CM_ "IMPORT _nissan_common.dbc";

BO_ 348 GAS_PEDAL: 8 XXX
 SG_ GAS_PEDAL_RAW : 26|11@0+ (1,0) [0|2047] "" XXX
 SG_ GAS_PEDAL : 47|10@0+ (1,0) [0|1023] "" XXX

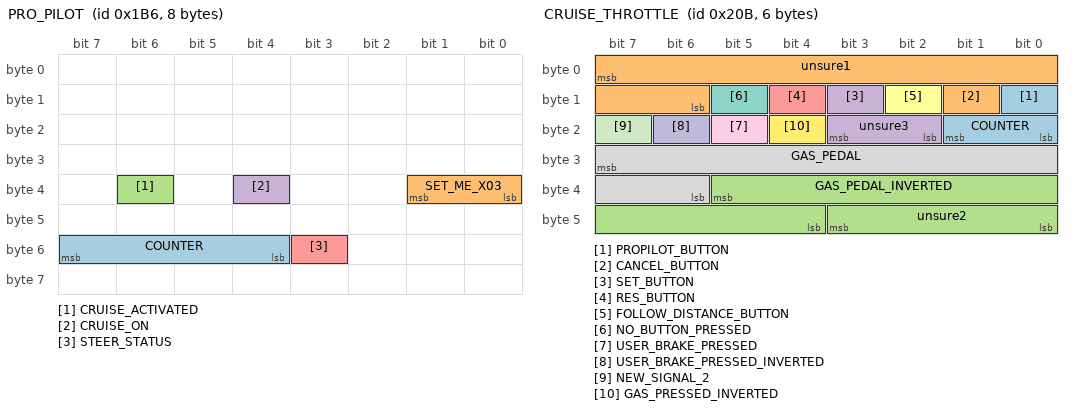
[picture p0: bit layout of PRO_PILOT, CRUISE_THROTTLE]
BO_ 438 PRO_PILOT: 8 XXX
 SG_ COUNTER : 55|4@0+ (1,0) [0|255] "" XXX
 SG_ SET_ME_X03 : 33|2@0+ (1,0) [0|15] "" XXX
 SG_ CRUISE_ACTIVATED : 38|1@0+ (1,0) [0|3] "" XXX
 SG_ CRUISE_ON : 36|1@0+ (1,0) [0|255] "" XXX
 SG_ STEER_STATUS : 51|1@0+ (1,0) [0|3] "" XXX

BO_ 523 CRUISE_THROTTLE: 6 XXX
 SG_ PROPILOT_BUTTON : 8|1@0+ (1,0) [0|1] "" XXX
 SG_ CANCEL_BUTTON : 9|1@0+ (1,0) [0|1] "" XXX
 SG_ GAS_PEDAL_INVERTED : 37|10@0+ (1,0) [0|1023] "" XXX
 SG_ SET_BUTTON : 11|1@0+ (1,0) [0|1] "" XXX
 SG_ RES_BUTTON : 12|1@0+ (1,0) [0|1] "" XXX
 SG_ FOLLOW_DISTANCE_BUTTON : 10|1@0+ (1,0) [0|1] "" XXX
 SG_ NO_BUTTON_PRESSED : 13|1@0+ (1,0) [0|1] "" XXX
 SG_ GAS_PEDAL : 31|10@0+ (1,0) [0|255] "" XXX
 SG_ USER_BRAKE_PRESSED : 21|1@0+ (1,0) [0|1] "" XXX
 SG_ USER_BRAKE_PRESSED_INVERTED : 22|1@0+ (1,0) [0|3] "" XXX
 SG_ NEW_SIGNAL_2 : 23|1@0+ (1,0) [0|1] "" XXX
 SG_ GAS_PRESSED_INVERTED : 20|1@0+ (1,0) [0|255] "" XXX
 SG_ COUNTER : 17|2@0+ (1,0) [0|3] "" XXX
 SG_ unsure1 : 7|10@0+ (1,0) [0|1023] "" XXX
 SG_ unsure2 : 43|4@0+ (1,0) [0|1] "" XXX
 SG_ unsure3 : 19|2@0+ (1,0) [0|3] "" XXX

BO_ 665 ESP: 8 XXX
 SG_ ESP_DISABLED : 24|1@0+ (1,0) [0|1] "" XXX

BO_ 666 WHEEL_SPEEDS_FRONT: 8 XXX
 SG_ WHEEL_SPEED_FR : 7|16@0+ (0.005,0) [0|65535] "KPH" XXX
 SG_ WHEEL_SPEED_FL : 23|16@0+ (0.005,0) [0|65535] "KPH" XXX

BO_ 768 STEER_TORQUE_SENSOR2: 2 XXX
 SG_ STEERING_TORQUE : 6|7@0+ (1,0) [0|127] "" XXX
 SG_ STEERING_PRESSED : 15|1@0+ (-1,1) [0|7] "" XXX

BO_ 1055 GEARBOX: 2 XXX
 SG_ SPORTS_MODE : 13|1@0+ (1,0) [0|1] "" XXX
 SG_ GEAR_SHIFTER : 5|3@0+ (1,0) [0|255] "" XXX

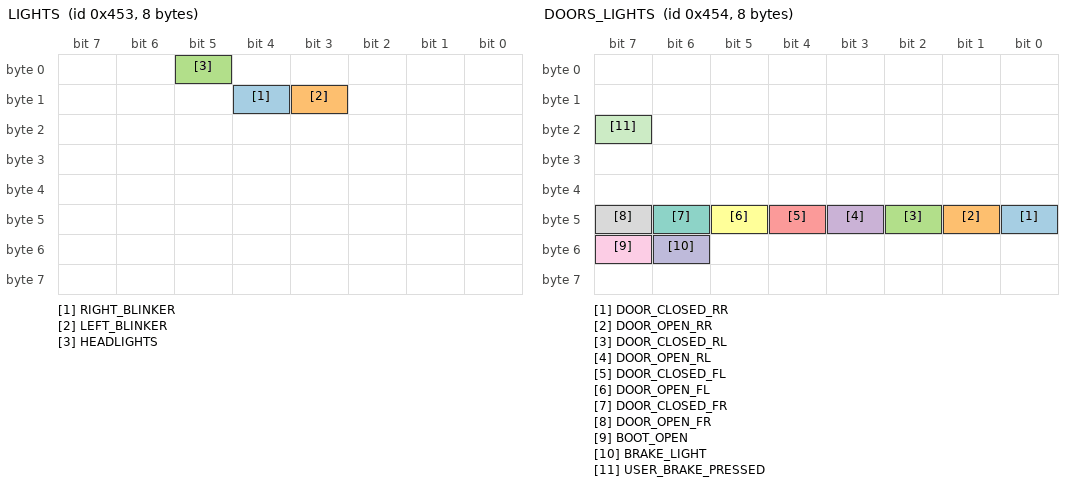
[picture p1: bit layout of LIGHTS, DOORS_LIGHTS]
BO_ 1107 LIGHTS: 8 XXX
 SG_ RIGHT_BLINKER : 12|1@0+ (1,0) [0|1] "" XXX
 SG_ LEFT_BLINKER : 11|1@0+ (1,0) [0|1] "" XXX
 SG_ HEADLIGHTS : 5|1@0+ (1,0) [0|1] "" XXX

BO_ 1108 DOORS_LIGHTS: 8 XXX
 SG_ DOOR_CLOSED_RR : 40|1@0+ (1,0) [0|1] "" XXX
 SG_ DOOR_OPEN_RR : 41|1@0+ (1,0) [0|1] "" XXX
 SG_ DOOR_CLOSED_RL : 42|1@0+ (1,0) [0|1] "" XXX
 SG_ DOOR_OPEN_RL : 43|1@0+ (1,0) [0|1] "" XXX
 SG_ DOOR_CLOSED_FL : 44|1@0+ (1,0) [0|1] "" XXX
 SG_ DOOR_OPEN_FL : 45|1@0+ (1,0) [0|1] "" XXX
 SG_ DOOR_CLOSED_FR : 46|1@0+ (1,0) [0|3] "" XXX
 SG_ DOOR_OPEN_FR : 47|1@0+ (1,0) [0|3] "" XXX
 SG_ BOOT_OPEN : 55|1@0+ (1,0) [0|1] "" XXX
 SG_ BRAKE_LIGHT : 54|1@0+ (1,0) [0|1] "" XXX
 SG_ USER_BRAKE_PRESSED : 23|1@0+ (1,0) [0|1] "" XXX

BO_ 1273 HUD: 7 XXX
 SG_ SEATBELT_DRIVER_LATCHED : 25|1@0+ (1,0) [0|1] "" XXX
 SG_ SPEED_MPH : 5|1@0+ (1,0) [0|1] "" XXX

VAL_ 1055 GEAR_SHIFTER 6 "L" 4 "D" 3 "N" 2 "R" 1 "P" ;
